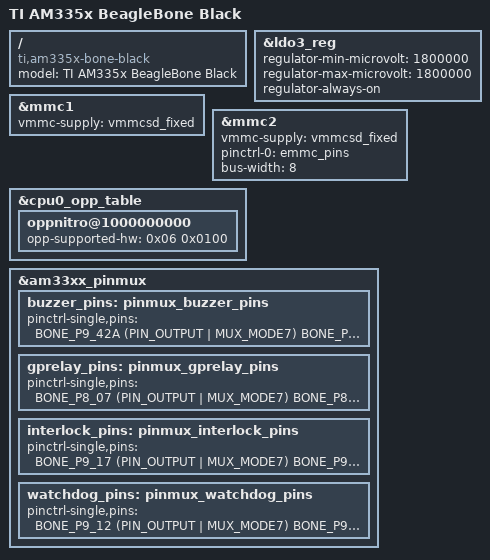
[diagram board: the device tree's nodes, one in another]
/*
 * Copyright (C) 2012 Texas Instruments Incorporated - http://www.ti.com/
 *
 * This program is free software; you can redistribute it and/or modify
 * it under the terms of the GNU General Public License version 2 as
 * published by the Free Software Foundation.
 */
/dts-v1/;

#include "am33xx.dtsi"
#include "am335x-bone-common.dtsi"
/* #include "am335x-bone-jtag.dtsi" */

/ {
	model = "TI AM335x BeagleBone Black";
	compatible = "ti,am335x-bone-black", "ti,am335x-bone", "ti,am33xx";
};

&ldo3_reg {
	regulator-min-microvolt = <1800000>;
	regulator-max-microvolt = <1800000>;
	regulator-always-on;
};

&mmc1 {
	vmmc-supply = <&vmmcsd_fixed>;
};

&mmc2 {
	vmmc-supply = <&vmmcsd_fixed>;
	pinctrl-names = "default";
	pinctrl-0 = <&emmc_pins>;
	bus-width = <8>;
	status = "okay";
};

&cpu0_opp_table {
	/*
	 * All PG 2.0 silicon may not support 1GHz but some of the early
	 * BeagleBone Blacks have PG 2.0 silicon which is guaranteed
	 * to support 1GHz OPP so enable it for PG 2.0 on this board.
	 */
	oppnitro@1000000000 {
		opp-supported-hw = <0x06 0x0100>;
	};
};


#include <dt-bindings/board/am335x-bbw-bbb-base.h>
/* Configuration of leds and buzzer */
&am33xx_pinmux {
	buzzer_pins: pinmux_buzzer_pins {
		pinctrl-single,pins = <
			BONE_P9_42A (PIN_OUTPUT | MUX_MODE7)
			BONE_P9_42B (PIN_INPUT | MUX_MODE7) /* Pin P9_42 is connected to two pads. Disable the second one by setting it to input */
		>;
	};

	gprelay_pins: pinmux_gprelay_pins {
		pinctrl-single,pins = <
			BONE_P8_07 (PIN_OUTPUT | MUX_MODE7)  /* Relay 01 */
			BONE_P8_09 (PIN_INPUT  | MUX_MODE7)
			BONE_P8_11 (PIN_OUTPUT | MUX_MODE7)  /* Relay 02 */
			BONE_P8_13 (PIN_INPUT  | MUX_MODE7)
			BONE_P8_15 (PIN_OUTPUT | MUX_MODE7)  /* Relay 03 */
			BONE_P8_17 (PIN_INPUT  | MUX_MODE7)
			BONE_P8_19 (PIN_OUTPUT | MUX_MODE7)  /* Relay 04 */
			BONE_P8_27 (PIN_INPUT  | MUX_MODE7)
			BONE_P8_08 (PIN_OUTPUT | MUX_MODE7)  /* Relay 05 */
			BONE_P8_10 (PIN_INPUT  | MUX_MODE7)
			BONE_P8_12 (PIN_OUTPUT | MUX_MODE7)  /* Relay 06 */
			BONE_P8_14 (PIN_INPUT  | MUX_MODE7)
			BONE_P8_16 (PIN_OUTPUT | MUX_MODE7)  /* Relay 07 */
			BONE_P8_18 (PIN_INPUT  | MUX_MODE7)
			BONE_P8_26 (PIN_OUTPUT | MUX_MODE7)  /* Relay 08 */
			BONE_P8_29 (PIN_INPUT  | MUX_MODE7)
		>;
	};

	interlock_pins: pinmux_interlock_pins {
		pinctrl-single,pins = <
			BONE_P9_17 (PIN_OUTPUT | MUX_MODE7) /* Interrupt command controlled by the Beaglebone */
			BONE_P9_15 (PIN_INPUT  | MUX_MODE7) /* Check of interlock status 1 */
			BONE_P9_18 (PIN_INPUT  | MUX_MODE7) /* Check of interlock status 2 */
			BONE_P9_16 (PIN_INPUT  | MUX_MODE7) /* Status of main interlock relays */
			BONE_P9_27 (PIN_INPUT  | MUX_MODE7) /* Status of KEY1 : main key */
			BONE_P9_28 (PIN_INPUT  | MUX_MODE7) /* Status of KEY2 : Beaglebone disable */
			BONE_P9_29 (PIN_INPUT  | MUX_MODE7) /* Status of KEY3 : Cryo disable */
		>;
	};
	
	watchdog_pins: pinmux_watchdog_pins {
		pinctrl-single,pins = <
			BONE_P9_12 (PIN_OUTPUT | MUX_MODE7) /* Enable hardware watchdog */
			BONE_P9_14 (PIN_OUTPUT | MUX_MODE7) /* Watchdog input */
		>;
	};
};

/* Include serial port configuration */
#include "am335x-bone-pinmux-ttyS1.dtsi"
#include "am335x-bone-pinmux-ttyS2.dtsi"
#include "am335x-bone-pinmux-ttyS4.dtsi"
#include "am335x-bone-pinmux-ttyS5.dtsi"

/* Include lcd configuration */
#include "am335x-peripheral-lcd0.dtsi"
